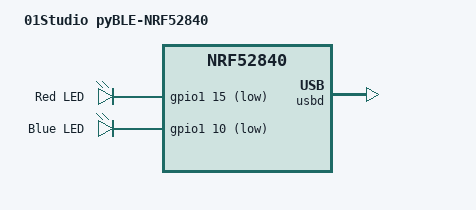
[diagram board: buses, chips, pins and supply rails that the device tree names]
/dts-v1/;
#include <nordic/nrf52840_qiaa.dtsi>

/ {
    model = "01Studio pyBLE-NRF52840";
    compatible = "nordic,nrf52840-qiaa";

    chosen {
        zephyr,console = &cdc_acm_uart0;
        zephyr,shell-uart = &cdc_acm_uart0;
    };

    leds {
        compatible = "gpio-leds";

        red_led: led_0 {
            gpios = <&gpio1 15 GPIO_ACTIVE_LOW>;
            label = "Red LED";
        };

        blue_led: led_1 {
            gpios = <&gpio1 10 GPIO_ACTIVE_LOW>;
            label = "Blue LED";
        };
    };
};

&usbd {
    status = "okay";
};

&gpio0 {
    status = "okay";
};

&gpio1 {
    status = "okay";
};

/* Disable QSPI completely */
&qspi {
    status = "disabled";
};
